VERSION ""

NS_ :

BS_:

BU_: XXX

BO_ 1416 NEW_MSG_1: 8 XXX
 SG_ NEW_SIGNAL_1 : 7|63@0+ (1,0) [0|9223372036854776000] "" XXX

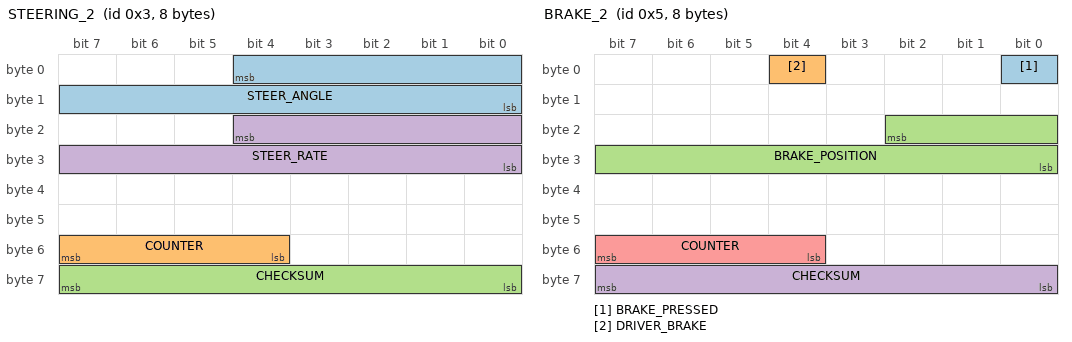
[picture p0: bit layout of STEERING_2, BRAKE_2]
BO_ 3 STEERING_2: 8 XXX
 SG_ STEER_ANGLE : 4|13@0+ (0.03418,0) [0|4095] "degrees" XXX
 SG_ COUNTER : 55|4@0+ (1,0) [0|15] "" XXX
 SG_ CHECKSUM : 56|8@1+ (1,0) [0|255] "" XXX
 SG_ STEER_RATE : 20|13@0+ (1,0) [0|8191] "" XXX

BO_ 5 BRAKE_2: 8 XXX
 SG_ BRAKE_PRESSED : 0|1@0+ (1,0) [0|1] "" XXX
 SG_ DRIVER_BRAKE : 4|1@0+ (1,0) [0|1] "" XXX
 SG_ BRAKE_POSITION : 18|11@0+ (1,0) [0|2047] "" XXX
 SG_ CHECKSUM : 56|8@1+ (1,0) [0|255] "" XXX
 SG_ COUNTER : 55|4@0+ (1,0) [0|15] "" XXX

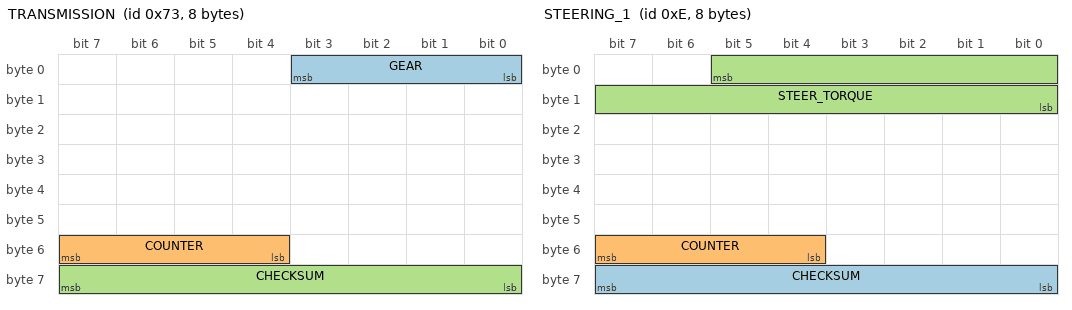
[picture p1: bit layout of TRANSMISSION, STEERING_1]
BO_ 115 TRANSMISSION: 8 XXX
 SG_ GEAR : 0|4@1+ (1,0) [0|15] "" XXX
 SG_ COUNTER : 55|4@0+ (1,0) [0|7] "" XXX
 SG_ CHECKSUM : 63|8@0+ (1,0) [0|255] "" XXX

BO_ 109 NEW_MSG_4: 8 XXX

BO_ 14 STEERING_1: 8 XXX
 SG_ CHECKSUM : 56|8@1+ (1,0) [0|255] "" XXX
 SG_ COUNTER : 55|4@0+ (1,0) [0|15] "" XXX
 SG_ STEER_TORQUE : 5|14@0+ (1,0) [0|16383] "" XXX

BO_ 767 NEW_MSG_6: 8 XXX

BO_ 255 NEW_MSG_7: 8 XXX
 SG_ NEW_SIGNAL_1 : 7|64@0+ (1,0) [0|65535] "" XXX

BO_ 461 NEW_MSG_8: 8 XXX

BO_ 95 BRAKE: 8 XXX

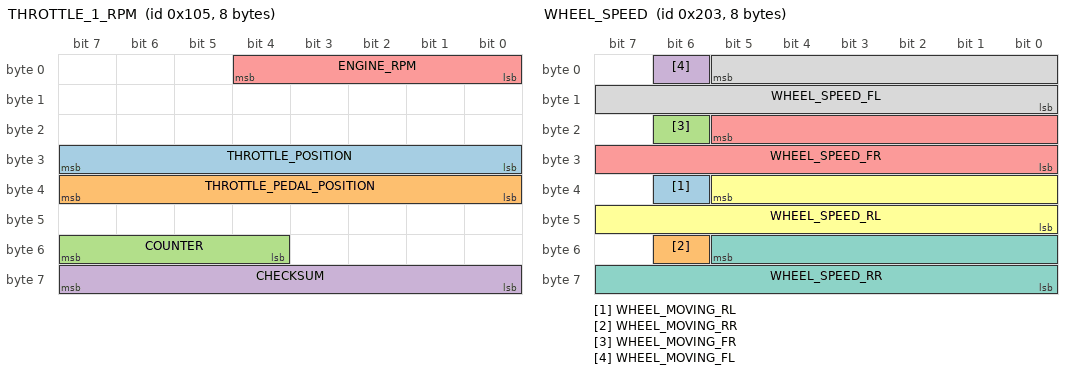
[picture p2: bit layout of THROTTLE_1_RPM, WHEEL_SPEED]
BO_ 261 THROTTLE_1_RPM: 8 XXX
 SG_ THROTTLE_POSITION : 31|8@0+ (1,0) [0|255] "" XXX
 SG_ THROTTLE_PEDAL_POSITION : 32|8@1+ (1,0) [0|255] "" XXX
 SG_ COUNTER : 55|4@0+ (1,0) [0|15] "" XXX
 SG_ CHECKSUM : 56|8@1+ (1,0) [0|255] "" XXX
 SG_ ENGINE_RPM : 4|5@0+ (250,0) [0|31] "RPM" XXX

BO_ 783 NEW_MSG_11: 8 XXX
 SG_ NEW_SIGNAL_1 : 55|8@0+ (1,0) [0|255] "" XXX

BO_ 515 WHEEL_SPEED: 8 XXX
 SG_ WHEEL_MOVING_RL : 38|1@0+ (1,0) [0|1] "" XXX
 SG_ WHEEL_MOVING_RR : 54|1@0+ (1,0) [0|1] "" XXX
 SG_ WHEEL_MOVING_FR : 22|1@0+ (1,0) [0|1] "" XXX
 SG_ WHEEL_MOVING_FL : 6|1@0+ (1,0) [0|1] "" XXX
 SG_ WHEEL_SPEED_FR : 21|14@0+ (0.0375,0) [0|300] "MPH" XXX
 SG_ WHEEL_SPEED_RL : 37|14@0+ (0.0375,0) [0|300] "MPH" XXX
 SG_ WHEEL_SPEED_RR : 53|14@0+ (0.0375,0) [0|300] "MPH" XXX
 SG_ WHEEL_SPEED_FL : 5|14@0+ (0.0375,0) [0|300] "MPH" XXX

BO_ 331 THROTTLE_2: 8 XXX

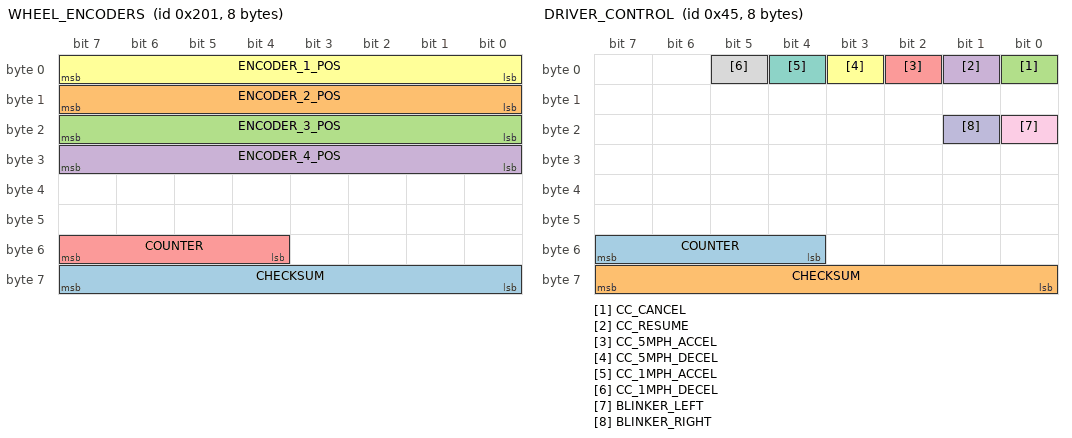
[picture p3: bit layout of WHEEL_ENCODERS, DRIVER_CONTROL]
BO_ 513 WHEEL_ENCODERS: 8 XXX
 SG_ CHECKSUM : 63|8@0+ (1,0) [0|255] "" XXX
 SG_ ENCODER_2_POS : 15|8@0+ (1,0) [0|255] "" XXX
 SG_ ENCODER_3_POS : 23|8@0+ (1,0) [0|255] "" XXX
 SG_ ENCODER_4_POS : 31|8@0+ (1,0) [0|255] "" XXX
 SG_ COUNTER : 55|4@0+ (1,0) [0|15] "" XXX
 SG_ ENCODER_1_POS : 7|8@0+ (1,0) [0|255] "" XXX

BO_ 643 DOORS: 8 XXX
 SG_ PASSENGER_DOOR : 2|2@1+ (1,0) [0|3] "" XXX
 SG_ REAR_PASSENGER_DRIVER : 5|3@0+ (1,0) [0|3] "" XXX
 SG_ REAR_PASSENGER_PASSENGER : 7|3@0+ (1,0) [0|3] "" XXX
 SG_ BRAKE_PRESSED : 27|1@0+ (1,0) [0|1] "" XXX
 SG_ DRIVER_DOOR : 1|2@0+ (1,0) [0|17] "" XXX

BO_ 257 CRUISE_CONTROL: 8 XXX
 SG_ CRUISE_ON : 6|1@0+ (1,0) [0|1] "" XXX

BO_ 69 DRIVER_CONTROL: 8 XXX
 SG_ COUNTER : 55|4@0+ (1,0) [0|15] "" XXX
 SG_ CHECKSUM : 56|8@1+ (1,0) [0|255] "" XXX
 SG_ CC_CANCEL : 0|1@0+ (1,0) [0|1] "" XXX
 SG_ CC_RESUME : 1|1@0+ (1,0) [0|1] "" XXX
 SG_ CC_5MPH_ACCEL : 2|1@0+ (1,0) [0|1] "" XXX
 SG_ CC_5MPH_DECEL : 3|1@0+ (1,0) [0|1] "" XXX
 SG_ CC_1MPH_ACCEL : 4|1@0+ (1,0) [0|1] "" XXX
 SG_ CC_1MPH_DECEL : 5|1@0+ (1,0) [0|1] "" XXX
 SG_ BLINKER_LEFT : 16|1@1+ (1,0) [0|3] "" XXX
 SG_ BLINKER_RIGHT : 17|1@0+ (1,0) [0|1] "" XXX

BO_ 260 CRUISE_CONTROL_2: 8 XXX

BO_ 888 CRUISE_CONTROL_3: 8 XXX
 SG_ CRUISE_SET_UP_DOWN : 15|8@0+ (1,0) [0|255] "" XXX

BO_ 885 SEATBELT: 8 XXX
 SG_ PASSENGER_BELT : 18|1@0+ (1,0) [0|1] "" XXX
 SG_ DRIVER_BELT : 16|1@0+ (1,0) [0|1] "" XXX
